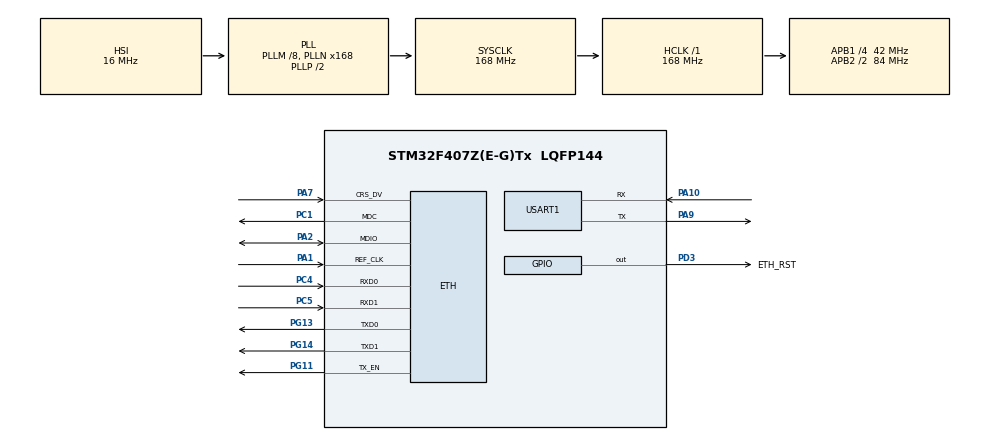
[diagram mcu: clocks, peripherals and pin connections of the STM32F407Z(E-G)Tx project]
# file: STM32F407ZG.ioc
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ETH.MACAddr=00\:80\:E1\:00\:00\:01
ETH.MediaInterface=ETH_MEDIA_INTERFACE_RMII
ETH.PHY_Name_RMII=userPHY
ETH.PHY_SR=31
ETH.PHY_User_Name=LAN8720
ETH.PhyAddress=0
FREERTOS.Tasks01=defaultTask,24,128,StartDefaultTask,Default,NULL,Dynamic,NULL,NULL
LWIP.GATEWAY_ADDRESS=192.168.003.001
LWIP.IP_ADDRESS=192.168.003.047
LWIP.LWIP_DHCP=1
LWIP.LWIP_NETIF_EXT_STATUS_CALLBACK=1
LWIP.LWIP_NETIF_STATUS_CALLBACK=1
LWIP.LWIP_UDPLITE=1
LWIP.NETMASK_ADDRESS=255.255.255.000
LWIP.Version=v2.1.2_Cube
Mcu.Family=STM32F4
Mcu.Name=STM32F407Z(E-G)Tx
Mcu.Package=LQFP144
NVIC.ETH_IRQn=true\:5\:0\:false\:false\:true\:true\:false\:true
NVIC.PriorityGroup=NVIC_PRIORITYGROUP_4
NVIC.TIM1_UP_TIM10_IRQn=true\:0\:0\:false\:false\:true\:false\:false\:true
NVIC.TimeBase=TIM1_UP_TIM10_IRQn
NVIC.TimeBaseIP=TIM1
PA1.Mode=RMII
PA1.Signal=ETH_REF_CLK
PA10.Mode=Asynchronous
PA10.Signal=USART1_RX
PA2.Mode=RMII
PA2.Signal=ETH_MDIO
PA7.Mode=RMII
PA7.Signal=ETH_CRS_DV
PA9.Mode=Asynchronous
PA9.Signal=USART1_TX
PC1.Mode=RMII
PC1.Signal=ETH_MDC
PC14-OSC32_IN.Mode=LSE-External-Oscillator
PC14-OSC32_IN.Signal=RCC_OSC32_IN
PC15-OSC32_OUT.Mode=LSE-External-Oscillator
PC15-OSC32_OUT.Signal=RCC_OSC32_OUT
PC4.Mode=RMII
PC4.Signal=ETH_RXD0
PC5.Mode=RMII
PC5.Signal=ETH_RXD1
PD3.GPIO_Label=ETH_RST
PD3.Signal=GPIO_Output
PG11.Mode=RMII
PG11.Signal=ETH_TX_EN
PG13.Mode=RMII
PG13.Signal=ETH_TXD0
PG14.Mode=RMII
PG14.Signal=ETH_TXD1
PH0-OSC_IN.Mode=HSE-External-Oscillator
PH0-OSC_IN.Signal=RCC_OSC_IN
PH1-OSC_OUT.Mode=HSE-External-Oscillator
PH1-OSC_OUT.Signal=RCC_OSC_OUT
ProjectManager.HeapSize=0x1000
ProjectManager.StackSize=0x2000
ProjectManager.TargetToolchain=MDK-ARM V5.27
RCC.48MHZClocksFreq_Value=84000000
RCC.AHBFreq_Value=168000000
RCC.APB1CLKDivider=RCC_HCLK_DIV4
RCC.APB1Freq_Value=42000000
RCC.APB1TimFreq_Value=84000000
RCC.APB2CLKDivider=RCC_HCLK_DIV2
RCC.APB2Freq_Value=84000000
RCC.APB2TimFreq_Value=168000000
RCC.CortexFreq_Value=168000000
RCC.HCLKFreq_Value=168000000
RCC.HSE_VALUE=8000000
RCC.HSI_VALUE=16000000
RCC.PLLM=8
RCC.PLLN=168
RCC.SYSCLKFreq_VALUE=168000000
RCC.SYSCLKSource=RCC_SYSCLKSOURCE_PLLCLK
RCC.VCOOutputFreq_Value=336000000
USART1.VirtualMode=VM_ASYNC
VP_FREERTOS_VS_CMSIS_V2.Mode=CMSIS_V2
VP_LWIP_VS_Enabled.Mode=Enabled
VP_SYS_VS_tim1.Mode=TIM1
board=custom

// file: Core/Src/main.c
/* USER CODE BEGIN Header */
/**
  ******************************************************************************
  * @file           : main.c
  * @brief          : Main program body
  ******************************************************************************
  * @attention
  *
  * <h2><center>&copy; Copyright (c) 2021 STMicroelectronics.
  * All rights reserved.</center></h2>
  *
  * This software component is licensed by ST under Ultimate Liberty license
  * SLA0044, the "License"; You may not use this file except in compliance with
  * the License. You may obtain a copy of the License at:
  *                             www.st.com/SLA0044
  *
  ******************************************************************************
  */
/* USER CODE END Header */
#include "main.h"
#include "cmsis_os.h"
#include "lwip.h"
#include "usart.h"
#include "gpio.h"

/* USER CODE BEGIN Includes */
#include "stdio.h"
/* USER CODE END Includes */

void SystemClock_Config(void);
void MX_FREERTOS_Init(void);

/* USER CODE BEGIN 0 */
// 重定向printf函数
int fputc(int ch,FILE *f)
{
    uint8_t temp[1]={ch};
    HAL_UART_Transmit(&huart1,temp,1,2);
	return 0;
}

/* USER CODE END 0 */

int main(void)
{

  /* MCU Configuration--------------------------------------------------------*/

  /* Reset of all peripherals, Initializes the Flash interface and the Systick. */
  HAL_Init();

  /* Configure the system clock */
  SystemClock_Config();

  /* Initialize all configured peripherals */
  MX_GPIO_Init();
  MX_USART1_UART_Init();

  /* Init scheduler */
  osKernelInitialize();  /* Call init function for freertos objects (in freertos.c) */
  MX_FREERTOS_Init();
  /* Start scheduler */
  osKernelStart();

  /* We should never get here as control is now taken by the scheduler */
  /* Infinite loop */
  while (1)
  {

  }
}

void SystemClock_Config(void)
{
  RCC_OscInitTypeDef RCC_OscInitStruct = {0};
  RCC_ClkInitTypeDef RCC_ClkInitStruct = {0};

  /** Configure the main internal regulator output voltage
  */
  __HAL_RCC_PWR_CLK_ENABLE();
  __HAL_PWR_VOLTAGESCALING_CONFIG(PWR_REGULATOR_VOLTAGE_SCALE1);
  /** Initializes the RCC Oscillators according to the specified parameters
  * in the RCC_OscInitTypeDef structure.
  */
  RCC_OscInitStruct.OscillatorType = RCC_OSCILLATORTYPE_HSI;
  RCC_OscInitStruct.HSIState = RCC_HSI_ON;
  RCC_OscInitStruct.HSICalibrationValue = RCC_HSICALIBRATION_DEFAULT;
  RCC_OscInitStruct.PLL.PLLState = RCC_PLL_ON;
  RCC_OscInitStruct.PLL.PLLSource = RCC_PLLSOURCE_HSI;
  RCC_OscInitStruct.PLL.PLLM = 8;
  RCC_OscInitStruct.PLL.PLLN = 168;
  RCC_OscInitStruct.PLL.PLLP = RCC_PLLP_DIV2;
  RCC_OscInitStruct.PLL.PLLQ = 4;
  if (HAL_RCC_OscConfig(&RCC_OscInitStruct) != HAL_OK)
  {
    Error_Handler();
  }
  /** Initializes the CPU, AHB and APB buses clocks
  */
  RCC_ClkInitStruct.ClockType = RCC_CLOCKTYPE_HCLK|RCC_CLOCKTYPE_SYSCLK
                              |RCC_CLOCKTYPE_PCLK1|RCC_CLOCKTYPE_PCLK2;
  RCC_ClkInitStruct.SYSCLKSource = RCC_SYSCLKSOURCE_PLLCLK;
  RCC_ClkInitStruct.AHBCLKDivider = RCC_SYSCLK_DIV1;
  RCC_ClkInitStruct.APB1CLKDivider = RCC_HCLK_DIV4;
  RCC_ClkInitStruct.APB2CLKDivider = RCC_HCLK_DIV2;

  if (HAL_RCC_ClockConfig(&RCC_ClkInitStruct, FLASH_LATENCY_5) != HAL_OK)
  {
    Error_Handler();
  }
}

 /**
  * @brief  Period elapsed callback in non blocking mode
  * @note   This function is called  when TIM1 interrupt took place, inside
  * HAL_TIM_IRQHandler(). It makes a direct call to HAL_IncTick() to increment
  * a global variable "uwTick" used as application time base.
  * @param  htim : TIM handle
  * @retval None
  */
void HAL_TIM_PeriodElapsedCallback(TIM_HandleTypeDef *htim)
{
  if (htim->Instance == TIM1) {
    HAL_IncTick();
  }
}

void Error_Handler(void)
{
  __disable_irq();
  while (1)
  {
  }
}

/************************ (C) COPYRIGHT STMicroelectronics *****END OF FILE****/
